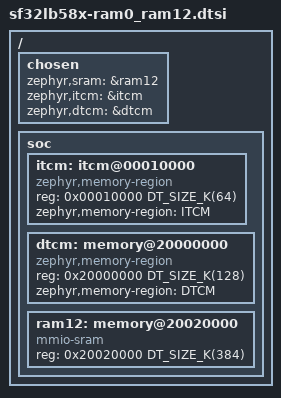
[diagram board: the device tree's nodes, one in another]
/*
 * Copyright (c) 2026 Qingsong Gou <gouqs@hotmail.com>
 * SPDX-License-Identifier: Apache-2.0
 */

#include <mem.h>

/ {
	chosen {
		zephyr,sram = &ram12;
		zephyr,itcm = &itcm;
		zephyr,dtcm = &dtcm;
	};

	soc {
		itcm: itcm@00010000 {
			compatible = "zephyr,memory-region", "mmio-sram";
			reg = <0x00010000 DT_SIZE_K(64)>;
			zephyr,memory-region = "ITCM";
		};

		dtcm: memory@20000000 {
			compatible = "zephyr,memory-region", "arm,dtcm";
			reg = <0x20000000 DT_SIZE_K(128)>;
			zephyr,memory-region = "DTCM";
		};

		ram12: memory@20020000 {
			compatible = "mmio-sram";
			reg = <0x20020000 DT_SIZE_K(384)>;
		};
	};
};
